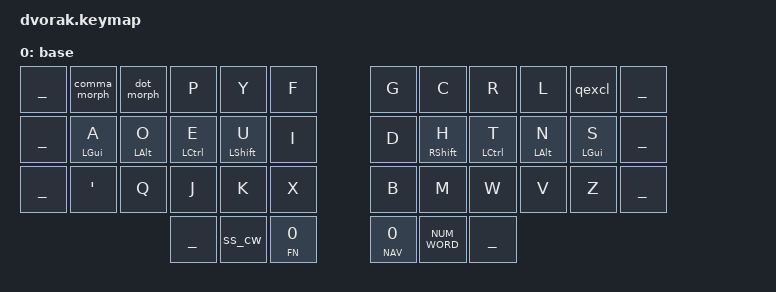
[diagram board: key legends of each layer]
ZMK_LAYER(base, // 0
//╭─────────────┬─────────────┬─────────────┬─────────────┬─────────────┬─────────────╮ ╭─────────────┬─────────────┬─────────────┬─────────────┬─────────────┬─────────────╮
    ___           &comma_morph  &dot_morph    &kp P         &kp Y         &kp F           &kp G         &kp C         &kp R         &kp L         &qexcl        ___
//├─────────────┼─────────────┼─────────────┼─────────────┼─────────────┼─────────────┤ ├─────────────┼─────────────┼─────────────┼─────────────┼─────────────┴─────────────┤
    ___           &hml LGUI A   &hml LALT O   &hml LCTRL E  &hml LSHFT U  &kp I           &kp D         &hmr RSHFT H  &hmr LCTRL T  &hmr LALT N   &hmr LGUI S   ___
//├─────────────┼─────────────┼─────────────┼─────────────┼─────────────┼─────────────┤ ├─────────────┼─────────────┼─────────────┼─────────────┼─────────────┴─────────────┤
    ___           &kp SQT       &kp Q         &kp J         &kp K         &kp X           &kp B         &kp M         &kp W         &kp V         &kp Z         ___
//╰─────────────┴─────────────┴─────────────┼─────────────┼─────────────┼─────────────┤ ├─────────────┼─────────────┼─────────────┼─────────────┴─────────────┴─────────────╯
                                              ___           &ss_cw        &lt_bspc FN 0   &lt_spc NAV 0 NUM_WORD      ___
//                                          ╰─────────────┴─────────────┴─────────────╯ ╰─────────────┴─────────────┴─────────────╯
)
